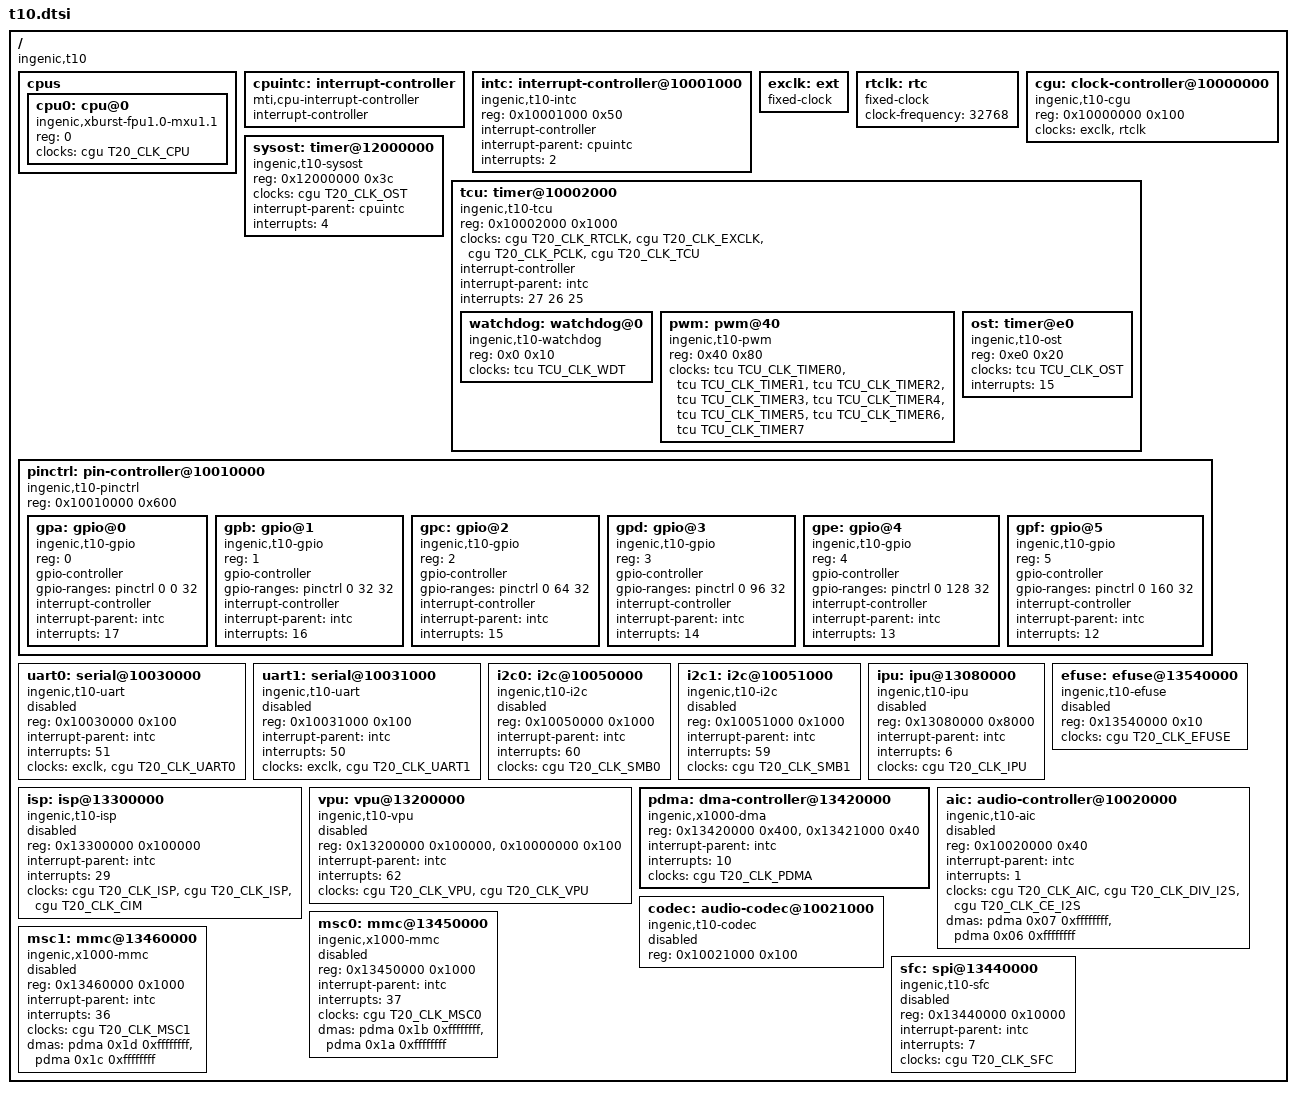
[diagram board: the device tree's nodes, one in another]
// SPDX-License-Identifier: GPL-2.0
#include <dt-bindings/clock/ingenic,tcu.h>
/* The T10 uses the T20 clock IDs; it has no VPLL, LCD, CSI or UART2 clock */
#include <dt-bindings/clock/ingenic,t20-cgu.h>

/ {
	#address-cells = <1>;
	#size-cells = <1>;
	compatible = "ingenic,t10";

	cpus {
		#address-cells = <1>;
		#size-cells = <0>;

		cpu0: cpu@0 {
			device_type = "cpu";
			compatible = "ingenic,xburst-fpu1.0-mxu1.1";
			reg = <0>;

			clocks = <&cgu T20_CLK_CPU>;
			clock-names = "cpu";
		};
	};

	cpuintc: interrupt-controller {
		#address-cells = <0>;
		#interrupt-cells = <1>;
		interrupt-controller;
		compatible = "mti,cpu-interrupt-controller";
	};

	intc: interrupt-controller@10001000 {
		compatible = "ingenic,t10-intc", "ingenic,jz4780-intc";
		reg = <0x10001000 0x50>;

		interrupt-controller;
		#interrupt-cells = <1>;

		interrupt-parent = <&cpuintc>;
		interrupts = <2>;
	};

	exclk: ext {
		compatible = "fixed-clock";
		#clock-cells = <0>;
	};

	rtclk: rtc {
		compatible = "fixed-clock";
		#clock-cells = <0>;
		clock-frequency = <32768>;
	};

	cgu: clock-controller@10000000 {
		compatible = "ingenic,t10-cgu", "simple-mfd";
		reg = <0x10000000 0x100>;
		#address-cells = <1>;
		#size-cells = <1>;
		ranges = <0x0 0x10000000 0x100>;

		#clock-cells = <1>;

		clocks = <&exclk>, <&rtclk>;
		clock-names = "ext", "rtc";
	};

	sysost: timer@12000000 {
		compatible = "ingenic,t10-sysost", "ingenic,x1000-ost";
		reg = <0x12000000 0x3c>;

		#clock-cells = <1>;

		clocks = <&cgu T20_CLK_OST>;
		clock-names = "ost";

		interrupt-parent = <&cpuintc>;
		interrupts = <4>;
	};

	tcu: timer@10002000 {
		compatible = "ingenic,t10-tcu", "ingenic,jz4760-tcu",
			     "simple-mfd";
		reg = <0x10002000 0x1000>;
		#address-cells = <1>;
		#size-cells = <1>;
		ranges = <0x0 0x10002000 0x1000>;

		#clock-cells = <1>;

		clocks = <&cgu T20_CLK_RTCLK>,
			 <&cgu T20_CLK_EXCLK>,
			 <&cgu T20_CLK_PCLK>,
			 <&cgu T20_CLK_TCU>;
		clock-names = "rtc", "ext", "pclk", "tcu";

		interrupt-controller;
		#interrupt-cells = <1>;

		interrupt-parent = <&intc>;
		interrupts = <27 26 25>;

		watchdog: watchdog@0 {
			compatible = "ingenic,t10-watchdog",
				     "ingenic,jz4780-watchdog";
			reg = <0x0 0x10>;

			clocks = <&tcu TCU_CLK_WDT>;
			clock-names = "wdt";
		};

		pwm: pwm@40 {
			compatible = "ingenic,t10-pwm", "ingenic,jz4740-pwm";
			reg = <0x40 0x80>;

			#pwm-cells = <3>;

			clocks = <&tcu TCU_CLK_TIMER0>,
				 <&tcu TCU_CLK_TIMER1>,
				 <&tcu TCU_CLK_TIMER2>,
				 <&tcu TCU_CLK_TIMER3>,
				 <&tcu TCU_CLK_TIMER4>,
				 <&tcu TCU_CLK_TIMER5>,
				 <&tcu TCU_CLK_TIMER6>,
				 <&tcu TCU_CLK_TIMER7>;
			clock-names = "timer0", "timer1", "timer2", "timer3",
				      "timer4", "timer5", "timer6", "timer7";
		};

		ost: timer@e0 {
			compatible = "ingenic,t10-ost", "ingenic,jz4760b-ost";
			reg = <0xe0 0x20>;

			clocks = <&tcu TCU_CLK_OST>;
			clock-names = "ost";

			interrupts = <15>;
		};
	};

	pinctrl: pin-controller@10010000 {
		compatible = "ingenic,t10-pinctrl";
		reg = <0x10010000 0x600>;

		#address-cells = <1>;
		#size-cells = <0>;

		gpa: gpio@0 {
			compatible = "ingenic,t10-gpio";
			reg = <0>;

			gpio-controller;
			gpio-ranges = <&pinctrl 0 0 32>;
			#gpio-cells = <2>;

			interrupt-controller;
			#interrupt-cells = <2>;

			interrupt-parent = <&intc>;
			interrupts = <17>;
		};

		gpb: gpio@1 {
			compatible = "ingenic,t10-gpio";
			reg = <1>;

			gpio-controller;
			gpio-ranges = <&pinctrl 0 32 32>;
			#gpio-cells = <2>;

			interrupt-controller;
			#interrupt-cells = <2>;

			interrupt-parent = <&intc>;
			interrupts = <16>;
		};

		gpc: gpio@2 {
			compatible = "ingenic,t10-gpio";
			reg = <2>;

			gpio-controller;
			gpio-ranges = <&pinctrl 0 64 32>;
			#gpio-cells = <2>;

			interrupt-controller;
			#interrupt-cells = <2>;

			interrupt-parent = <&intc>;
			interrupts = <15>;
		};

		gpd: gpio@3 {
			compatible = "ingenic,t10-gpio";
			reg = <3>;

			gpio-controller;
			gpio-ranges = <&pinctrl 0 96 32>;
			#gpio-cells = <2>;

			interrupt-controller;
			#interrupt-cells = <2>;

			interrupt-parent = <&intc>;
			interrupts = <14>;
		};

		gpe: gpio@4 {
			compatible = "ingenic,t10-gpio";
			reg = <4>;

			gpio-controller;
			gpio-ranges = <&pinctrl 0 128 32>;
			#gpio-cells = <2>;

			interrupt-controller;
			#interrupt-cells = <2>;

			interrupt-parent = <&intc>;
			interrupts = <13>;
		};

		gpf: gpio@5 {
			compatible = "ingenic,t10-gpio";
			reg = <5>;

			gpio-controller;
			gpio-ranges = <&pinctrl 0 160 32>;
			#gpio-cells = <2>;

			interrupt-controller;
			#interrupt-cells = <2>;

			interrupt-parent = <&intc>;
			interrupts = <12>;
		};
	};

	uart0: serial@10030000 {
		compatible = "ingenic,t10-uart", "ingenic,x1000-uart";
		reg = <0x10030000 0x100>;

		interrupt-parent = <&intc>;
		interrupts = <51>;

		clocks = <&exclk>, <&cgu T20_CLK_UART0>;
		clock-names = "baud", "module";

		status = "disabled";
	};

	uart1: serial@10031000 {
		compatible = "ingenic,t10-uart", "ingenic,x1000-uart";
		reg = <0x10031000 0x100>;

		interrupt-parent = <&intc>;
		interrupts = <50>;

		clocks = <&exclk>, <&cgu T20_CLK_UART1>;
		clock-names = "baud", "module";

		status = "disabled";
	};

	i2c0: i2c@10050000 {
		compatible = "ingenic,t10-i2c", "ingenic,x1000-i2c";
		reg = <0x10050000 0x1000>;

		interrupt-parent = <&intc>;
		interrupts = <60>;

		clocks = <&cgu T20_CLK_SMB0>;

		#address-cells = <1>;
		#size-cells = <0>;

		status = "disabled";
	};

	i2c1: i2c@10051000 {
		compatible = "ingenic,t10-i2c", "ingenic,x1000-i2c";
		reg = <0x10051000 0x1000>;

		interrupt-parent = <&intc>;
		interrupts = <59>;

		clocks = <&cgu T20_CLK_SMB1>;

		#address-cells = <1>;
		#size-cells = <0>;

		status = "disabled";
	};

	/*
	 * The IPU libimp draws its OSD with, through the out-of-tree ipu module
	 * (/dev/ipu). Disabled: the module makes its device from this node.
	 */
	ipu: ipu@13080000 {
		compatible = "ingenic,t10-ipu";
		reg = <0x13080000 0x8000>;

		interrupt-parent = <&intc>;
		interrupts = <6>;

		clocks = <&cgu T20_CLK_IPU>;
		clock-names = "ipu";

		status = "disabled";
	};

	/*
	 * The tx-isp out-of-tree driver registers its own VIC, ISP core, CSI and
	 * video-in platform devices; this node gives them the clocks, the INTC
	 * source and the CIM MCLK pad. The T10 has no CSI gate (and no MIPI
	 * receiver), so no "csi" clock.
	 */
	isp: isp@13300000 {
		compatible = "ingenic,t10-isp";
		reg = <0x13300000 0x100000>;

		interrupt-parent = <&intc>;
		interrupts = <29>;

		clocks = <&cgu T20_CLK_ISP>, <&cgu T20_CLK_ISP>,
			 <&cgu T20_CLK_CIM>;
		clock-names = "cgu_isp", "isp", "cgu_cim";

		status = "disabled";
	};

	/*
	 * The helix video engine behind the vendor soc-vpu driver; the second
	 * window is the CPM, whose SRBC register resets the engine.
	 */
	vpu: vpu@13200000 {
		compatible = "ingenic,t10-vpu";
		reg = <0x13200000 0x100000>, <0x10000000 0x100>;

		interrupt-parent = <&intc>;
		interrupts = <62>;

		clocks = <&cgu T20_CLK_VPU>, <&cgu T20_CLK_VPU>;
		clock-names = "vpu0", "cgu_vpu";

		status = "disabled";
	};

	efuse: efuse@13540000 {
		compatible = "ingenic,t10-efuse";
		reg = <0x13540000 0x10>;

		clocks = <&cgu T20_CLK_EFUSE>;

		status = "disabled";
	};

	pdma: dma-controller@13420000 {
		compatible = "ingenic,x1000-dma";
		reg = <0x13420000 0x400>, <0x13421000 0x40>;

		interrupt-parent = <&intc>;
		interrupts = <10>;

		clocks = <&cgu T20_CLK_PDMA>;

		#dma-cells = <2>;
	};

	aic: audio-controller@10020000 {
		compatible = "ingenic,t10-aic";
		reg = <0x10020000 0x40>;

		interrupt-parent = <&intc>;
		interrupts = <1>;

		clocks = <&cgu T20_CLK_AIC>,
			 <&cgu T20_CLK_DIV_I2S>,
			 <&cgu T20_CLK_CE_I2S>;
		clock-names = "gate_aic", "div_i2s", "ce_i2s";

		dmas = <&pdma 0x07 0xffffffff>,
		       <&pdma 0x06 0xffffffff>;
		dma-names = "rx", "tx";

		status = "disabled";
	};

	codec: audio-codec@10021000 {
		compatible = "ingenic,t10-codec";
		reg = <0x10021000 0x100>;

		status = "disabled";
	};

	msc0: mmc@13450000 {
		compatible = "ingenic,x1000-mmc";
		reg = <0x13450000 0x1000>;

		interrupt-parent = <&intc>;
		interrupts = <37>;

		clocks = <&cgu T20_CLK_MSC0>;
		clock-names = "mmc";

		dmas = <&pdma 0x1b 0xffffffff>,
		       <&pdma 0x1a 0xffffffff>;
		dma-names = "rx", "tx";

		status = "disabled";
	};

	msc1: mmc@13460000 {
		compatible = "ingenic,x1000-mmc";
		reg = <0x13460000 0x1000>;

		interrupt-parent = <&intc>;
		interrupts = <36>;

		clocks = <&cgu T20_CLK_MSC1>;
		clock-names = "mmc";

		dmas = <&pdma 0x1d 0xffffffff>,
		       <&pdma 0x1c 0xffffffff>;
		dma-names = "rx", "tx";

		status = "disabled";
	};

	sfc: spi@13440000 {
		compatible = "ingenic,t10-sfc", "ingenic,x1000-sfc";
		reg = <0x13440000 0x10000>;

		interrupt-parent = <&intc>;
		interrupts = <7>;

		clocks = <&cgu T20_CLK_SFC>;
		clock-names = "sfc";

		#address-cells = <1>;
		#size-cells = <0>;

		status = "disabled";
	};
};
